# iom480ae register map
Registers are 32-bit, access not given, no defined reset value unless marked. A register's access mark holds for its fields unless they carry their own. Addresses are absolute; registers are grouped by the start of their names; [hi:lo] are bit positions; {n}, {i} and the like mark numbered series.

## UART5
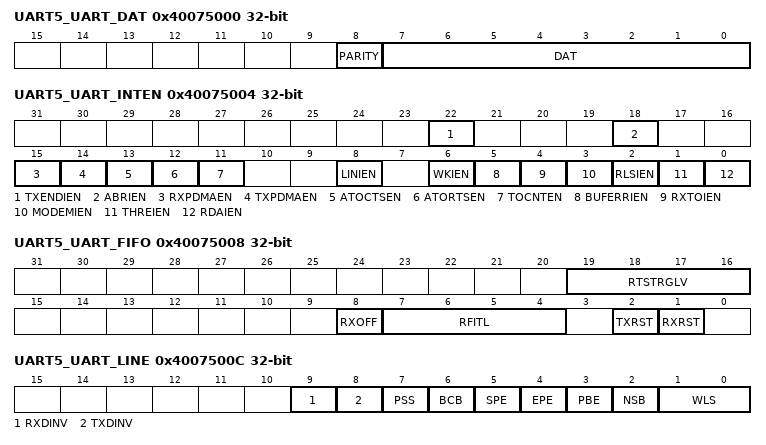
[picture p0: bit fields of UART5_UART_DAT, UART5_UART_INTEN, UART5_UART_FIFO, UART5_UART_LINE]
0x40075000 UART5_UART_DAT
  [8] PARITY, [7:0] DAT
0x40075004 UART5_UART_INTEN
  [22] TXENDIEN, [18] ABRIEN, [15] RXPDMAEN, [14] TXPDMAEN, [13] ATOCTSEN, [12] ATORTSEN, [11] TOCNTEN, [8] LINIEN, [6] WKIEN, [5] BUFERRIEN, [4] RXTOIEN, [3] MODEMIEN, [2] RLSIEN, [1] THREIEN, [0] RDAIEN
0x40075008 UART5_UART_FIFO
  [19:16] RTSTRGLV, [8] RXOFF, [7:4] RFITL, [2] TXRST, [1] RXRST
0x4007500C UART5_UART_LINE
  [9] RXDINV, [8] TXDINV, [7] PSS, [6] BCB, [5] SPE, [4] EPE, [3] PBE, [2] NSB, [1:0] WLS
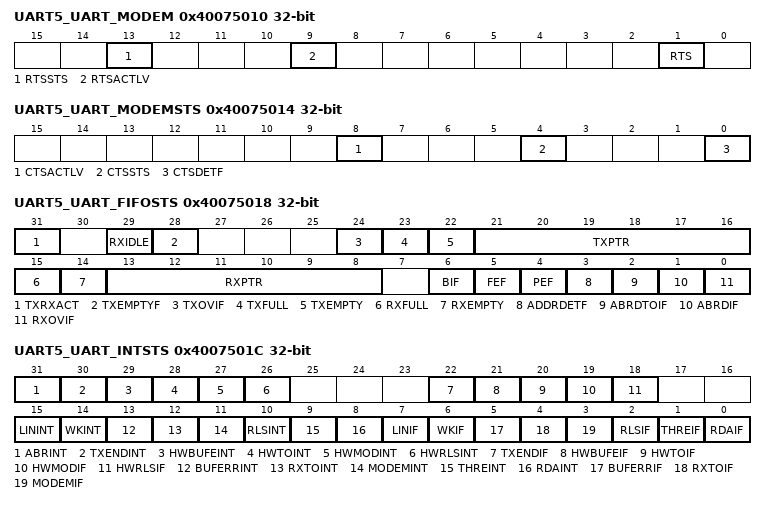
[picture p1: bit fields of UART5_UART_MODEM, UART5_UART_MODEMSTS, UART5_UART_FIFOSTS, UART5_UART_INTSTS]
0x40075010 UART5_UART_MODEM
  [13] RTSSTS, [9] RTSACTLV, [1] RTS
0x40075014 UART5_UART_MODEMSTS
  [8] CTSACTLV, [4] CTSSTS, [0] CTSDETF
0x40075018 UART5_UART_FIFOSTS
  [31] TXRXACT, [29] RXIDLE, [28] TXEMPTYF, [24] TXOVIF, [23] TXFULL, [22] TXEMPTY, [21:16] TXPTR, [15] RXFULL, [14] RXEMPTY, [13:8] RXPTR, [6] BIF, [5] FEF, [4] PEF, [3] ADDRDETF, [2] ABRDTOIF, [1] ABRDIF, [0] RXOVIF
0x4007501C UART5_UART_INTSTS
  [31] ABRINT, [30] TXENDINT, [29] HWBUFEINT, [28] HWTOINT, [27] HWMODINT, [26] HWRLSINT, [22] TXENDIF, [21] HWBUFEIF, [20] HWTOIF, [19] HWMODIF, [18] HWRLSIF, [15] LININT, [14] WKINT, [13] BUFERRINT, [12] RXTOINT, [11] MODEMINT, [10] RLSINT, [9] THREINT, [8] RDAINT, [7] LINIF, [6] WKIF, [5] BUFERRIF, [4] RXTOIF, [3] MODEMIF, [2] RLSIF, [1] THREIF, [0] RDAIF
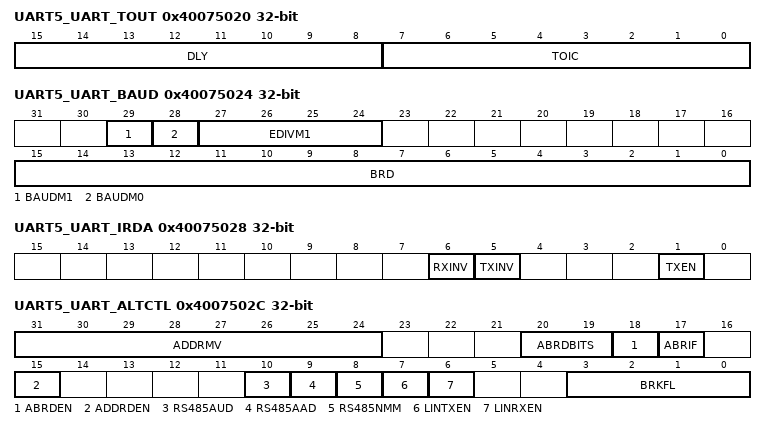
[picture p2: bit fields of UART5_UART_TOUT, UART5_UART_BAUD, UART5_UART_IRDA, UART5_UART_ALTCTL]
0x40075020 UART5_UART_TOUT
  [15:8] DLY, [7:0] TOIC
0x40075024 UART5_UART_BAUD
  [29] BAUDM1, [28] BAUDM0, [27:24] EDIVM1, [15:0] BRD
0x40075028 UART5_UART_IRDA
  [6] RXINV, [5] TXINV, [1] TXEN
0x4007502C UART5_UART_ALTCTL
  [31:24] ADDRMV, [20:19] ABRDBITS, [18] ABRDEN, [17] ABRIF, [15] ADDRDEN, [10] RS485AUD, [9] RS485AAD, [8] RS485NMM, [7] LINTXEN, [6] LINRXEN, [3:0] BRKFL
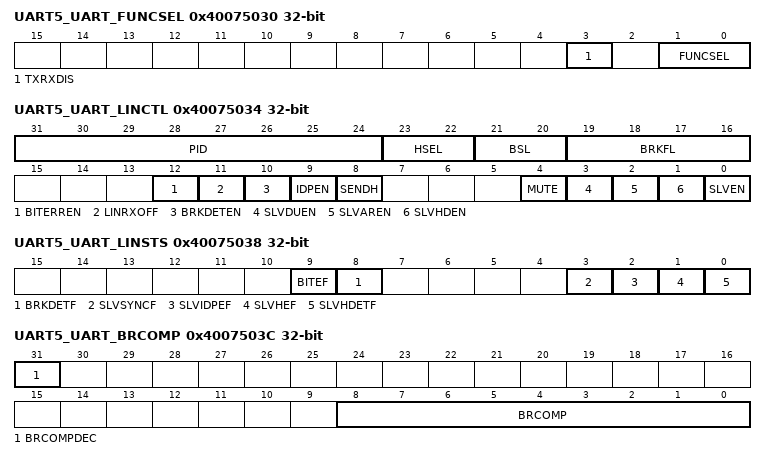
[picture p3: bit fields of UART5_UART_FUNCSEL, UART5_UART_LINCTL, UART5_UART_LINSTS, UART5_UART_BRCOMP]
0x40075030 UART5_UART_FUNCSEL
  [3] TXRXDIS, [1:0] FUNCSEL
0x40075034 UART5_UART_LINCTL
  [31:24] PID, [23:22] HSEL, [21:20] BSL, [19:16] BRKFL, [12] BITERREN, [11] LINRXOFF, [10] BRKDETEN, [9] IDPEN, [8] SENDH, [4] MUTE, [3] SLVDUEN, [2] SLVAREN, [1] SLVHDEN, [0] SLVEN
0x40075038 UART5_UART_LINSTS
  [9] BITEF, [8] BRKDETF, [3] SLVSYNCF, [2] SLVIDPEF, [1] SLVHEF, [0] SLVHDETF
0x4007503C UART5_UART_BRCOMP
  [31] BRCOMPDEC, [8:0] BRCOMP
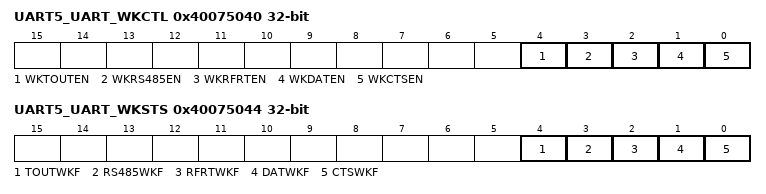
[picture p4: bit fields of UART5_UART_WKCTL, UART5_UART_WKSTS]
0x40075040 UART5_UART_WKCTL
  [4] WKTOUTEN, [3] WKRS485EN, [2] WKRFRTEN, [1] WKDATEN, [0] WKCTSEN
0x40075044 UART5_UART_WKSTS
  [4] TOUTWKF, [3] RS485WKF, [2] RFRTWKF, [1] DATWKF, [0] CTSWKF
0x40075048 UART5_UART_DWKCOMP
  [15:0] STCOMP

## EMAC
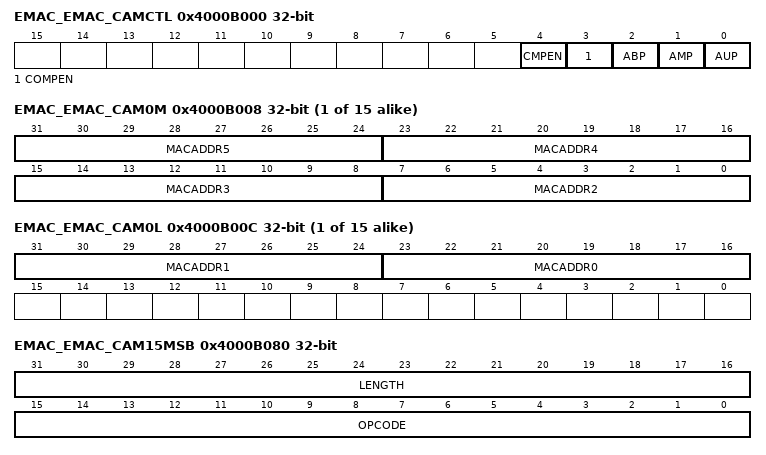
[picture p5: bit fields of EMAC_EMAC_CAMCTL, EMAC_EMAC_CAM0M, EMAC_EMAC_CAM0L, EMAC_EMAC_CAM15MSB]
0x4000B000 EMAC_EMAC_CAMCTL
  [4] CMPEN, [3] COMPEN, [2] ABP, [1] AMP, [0] AUP
0x4000B004 EMAC_ECAM_CAMEN
  [0] CAMxEN
{0x4000B008+8i} EMAC_EMAC_CAM{i}M (i=0..14)
  [8n-9:8n-16] MACADDR{n} (n=2..5)
{0x4000B00C+8i} EMAC_EMAC_CAM{i}L (i=0..14)
  [31:24] MACADDR1, [23:16] MACADDR0
0x4000B080 EMAC_EMAC_CAM15MSB
  [31:16] LENGTH, [15:0] OPCODE
0x4000B084 EMAC_EMAC_CAM15LSB
  [31:24] OPERAND
0x4000B088 EMAC_EMAC_TXDSA
0x4000B08C EMAC_EMAC_RXDSA
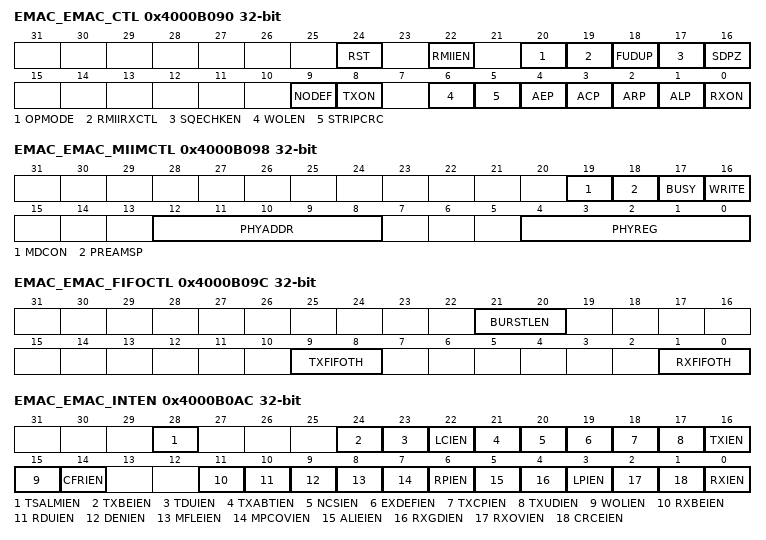
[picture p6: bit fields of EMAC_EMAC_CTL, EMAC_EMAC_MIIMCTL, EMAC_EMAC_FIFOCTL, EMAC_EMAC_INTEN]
0x4000B090 EMAC_EMAC_CTL
  [24] RST, [22] RMIIEN, [20] OPMODE, [19] RMIIRXCTL, [18] FUDUP, [17] SQECHKEN, [16] SDPZ, [9] NODEF, [8] TXON, [6] WOLEN, [5] STRIPCRC, [4] AEP, [3] ACP, [2] ARP, [1] ALP, [0] RXON
0x4000B094 EMAC_EMAC_MIIMDAT
  [15:0] DATA
0x4000B098 EMAC_EMAC_MIIMCTL
  [19] MDCON, [18] PREAMSP, [17] BUSY, [16] WRITE, [12:8] PHYADDR, [4:0] PHYREG
0x4000B09C EMAC_EMAC_FIFOCTL
  [21:20] BURSTLEN, [9:8] TXFIFOTH, [1:0] RXFIFOTH
0x4000B0A0 EMAC_EMAC_TXST
0x4000B0A4 EMAC_EMAC_RXST
0x4000B0A8 EMAC_EMAC_MRFL
  [15:0] MRFL
0x4000B0AC EMAC_EMAC_INTEN
  [28] TSALMIEN, [24] TXBEIEN, [23] TDUIEN, [22] LCIEN, [21] TXABTIEN, [20] NCSIEN, [19] EXDEFIEN, [18] TXCPIEN, [17] TXUDIEN, [16] TXIEN, [15] WOLIEN, [14] CFRIEN, [11] RXBEIEN, [10] RDUIEN, [9] DENIEN, [8] MFLEIEN, [7] MPCOVIEN, [6] RPIEN, [5] ALIEIEN, [4] RXGDIEN, [3] LPIEN, [2] RXOVIEN, [1] CRCEIEN, [0] RXIEN
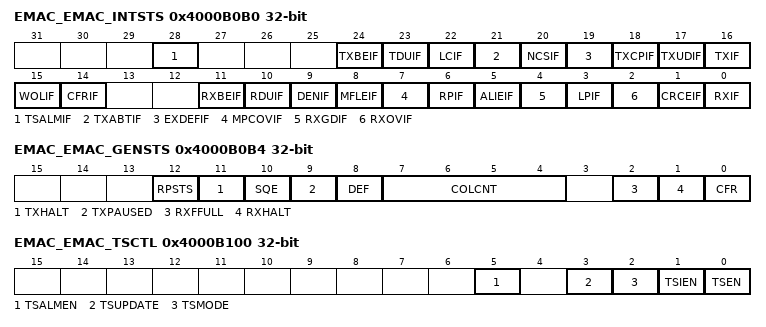
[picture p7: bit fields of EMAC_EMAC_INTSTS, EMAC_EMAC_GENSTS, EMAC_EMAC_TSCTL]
0x4000B0B0 EMAC_EMAC_INTSTS
  [28] TSALMIF, [24] TXBEIF, [23] TDUIF, [22] LCIF, [21] TXABTIF, [20] NCSIF, [19] EXDEFIF, [18] TXCPIF, [17] TXUDIF, [16] TXIF, [15] WOLIF, [14] CFRIF, [11] RXBEIF, [10] RDUIF, [9] DENIF, [8] MFLEIF, [7] MPCOVIF, [6] RPIF, [5] ALIEIF, [4] RXGDIF, [3] LPIF, [2] RXOVIF, [1] CRCEIF, [0] RXIF
0x4000B0B4 EMAC_EMAC_GENSTS
  [12] RPSTS, [11] TXHALT, [10] SQE, [9] TXPAUSED, [8] DEF, [7:4] COLCNT, [2] RXFFULL, [1] RXHALT, [0] CFR
0x4000B0B8 EMAC_EMAC_MPCNT
  [15:0] MPCNT
0x4000B0BC EMAC_EMAC_RPCNT
  [15:0] RPCNT
0x4000B0C8 EMAC_EMAC_FRSTS
  [15:0] RXFLT
0x4000B0CC EMAC_EMAC_CTXDSA
0x4000B0D0 EMAC_EMAC_CTXBSA
0x4000B0D4 EMAC_EMAC_CRXDSA
0x4000B0D8 EMAC_EMAC_CRXBSA
0x4000B100 EMAC_EMAC_TSCTL
  [5] TSALMEN, [3] TSUPDATE, [2] TSMODE, [1] TSIEN, [0] TSEN
0x4000B110 EMAC_EMAC_TSSEC
0x4000B114 EMAC_EMAC_TSSUBSEC
0x4000B118 EMAC_EMAC_TSINC
  [7:0] CNTINC
0x4000B11C EMAC_EMAC_TSADDEND
0x4000B120 EMAC_EMAC_UPDSEC
0x4000B124 EMAC_EMAC_UPDSUBSEC
0x4000B128 EMAC_EMAC_ALMSEC
0x4000B12C EMAC_EMAC_ALMSUBSEC
